# RL6955_IP_SVD register map
Vendor: Realtek
Registers are 32-bit, read-write, reset 0x0 unless marked. A register's access mark holds for its fields unless they carry their own. Offsets are from the block's base; [hi:lo] are bit positions; {n}, {i} and the like mark numbered series.

## MJPEG_REG
Base 0x418C0000
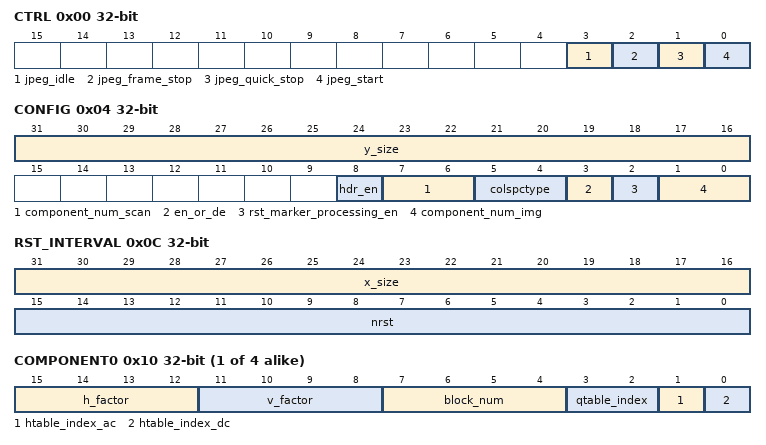
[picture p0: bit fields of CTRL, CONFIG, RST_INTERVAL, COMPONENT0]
0x00 CTRL access per field — MJPEG control register
  [3] jpeg_idle ro — jpeg idle status
  [2] jpeg_frame_stop wo — jpeg stop processing after current frame enc/dec done
  [1] jpeg_quick_stop wo — jpeg stop processing after current axi cmd complete.
  [0] jpeg_start wo — jpeg start processing
0x04 CONFIG — MJPEG config register
  [31:16] y_size — Number of lines in source image
  [8] hdr_en — Header Processing (generation/parsing) enabled when set
  [7:6] component_num_scan — Number of Components for Scan Header Marker Segment, minus one.
  [5:4] colspctype — colspctype defines the number of quantization tables to insert in the output stream minus one. 0 = Grayscale, 1 = YUV, 2 = RGB, 3 = CMYK
  [3] en_or_de — Selects encoding or decoding behavior. When this bit is set, the CODEC acts as a decoder; otherwise, it works as an encoder
  [2] rst_marker_processing_en — Enables restart marker processing when set. The ECS Encoder inserts restart markers every NRST +1 MCU
  [1:0] component_num_img — Number of color components in the source image minus 1. For example, in a grayscale image its value is 0; for a RGB or YUV image its value is = 2
0x08 MCUNUM — MJPEG MCU number register
  [25:0] mcu_num — Number of MCU units to encode minus 1
0x0C RST_INTERVAL — MJPEG reset interval control register
  [31:16] x_size — Number of pixels per line
  [15:0] nrst — NRST value is the number of MCUs between two restart markers minus 1. The content of this register is ignored if the rst_marker_processing_en bit is not set.
{0x10+4i} COMPONENT{i} (i=0..3) — MJPEG component register{i}
  [15:12] h_factor — Horizontal Sampling factor for component i.
  [11:8] v_factor — Vertical Sampling factor for component i.
  [7:4] block_num — The value is the number of data units (8 x 8 blocks of data) of the color component i contained in the MCU minus 1. The range is 0-15, because 4 bits are set aside for this field.
  [3:2] qtable_index — It indicates the quantization table to be used for the color component i. Since four quantization tables are possible, 2 bits are sufficient for this field (bits 3-2 in the register).
  [1] htable_index_ac — It selects the Huffman table for the encoding of the AC coefficients in the data units belonging to the color component i. Since only two AC tables are allowed in the baseline algorithm, one bit is sufficient (bit 1 in the register).
  [0] htable_index_dc — It bit selects the Huffman table for the encoding of the DC coefficient in the data units belonging to the color component i. Since only two DC tables are allowed in the baseline algorithm, one bit is sufficient (bit 0 in the register).
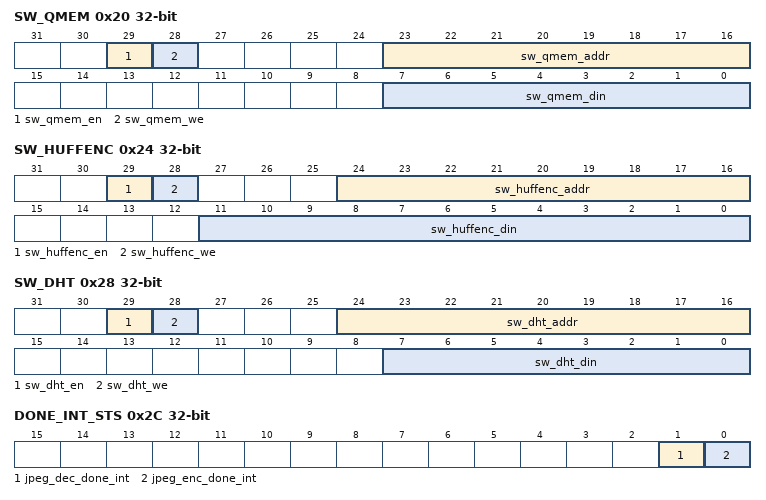
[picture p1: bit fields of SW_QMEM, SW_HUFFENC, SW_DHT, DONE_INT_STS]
0x20 SW_QMEM — MJPEG Qtable memory configuration
  [29] sw_qmem_en — Qtable configuration information, SRAM chip selection signal, write 1 when reading and writing
  [28] sw_qmem_we — Qtable configuration information, SRAM write enable
  [23:16] sw_qmem_addr — Qtable configuration information, selected address for SRAM
  [7:0] sw_qmem_din — Qtable configuration information, write SRAM value
0x24 SW_HUFFENC — MJPEG huffman memory configuration
  [29] sw_huffenc_en — huffman table configuration information, SRAM chip selection signal, write 1 when reading and writing
  [28] sw_huffenc_we — huffman table configuration information, SRAM write enable
  [24:16] sw_huffenc_addr — huffman table configuration information, selected address for SRAM
  [11:0] sw_huffenc_din — huffman table configuration information, write SRAM value
0x28 SW_DHT — MJPEG DQT memory configuration
  [29] sw_dht_en — DHT configuration information, SRAM chip selection signal, write 1 when reading and writing
  [28] sw_dht_we — DHT configuration information, SRAM write enable
  [24:16] sw_dht_addr — DHT configuration information, selected address for SRAM
  [7:0] sw_dht_din — DHT configuration information, write SRAM value
0x2C DONE_INT_STS ro — MJPEG encoder/decoder done interrupt status
  [1] jpeg_dec_done_int — JPEG decoding done interrupt (JPEG clock domain)
  [0] jpeg_enc_done_int — JPEG encoding done interrupt (JPEG clock domain)
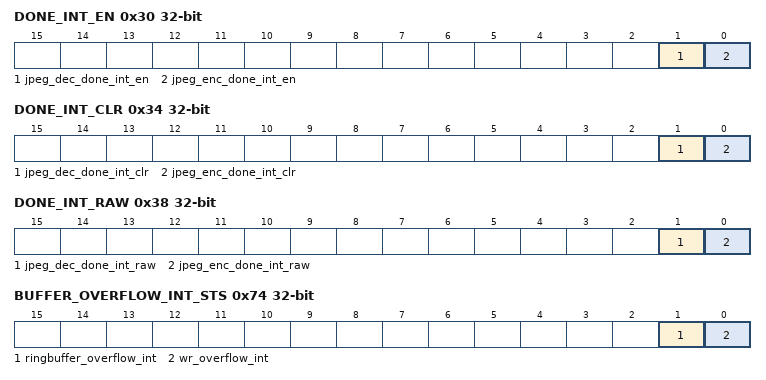
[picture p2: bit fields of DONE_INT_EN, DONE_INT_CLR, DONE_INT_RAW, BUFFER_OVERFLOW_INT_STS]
0x30 DONE_INT_EN — MJPEG encoder/decoder done interrupt enable signal
  [1] jpeg_dec_done_int_en — JPEG decoding interrupt enable signal
  [0] jpeg_enc_done_int_en — JPEG encoding interrupt enable signal
0x34 DONE_INT_CLR — MJPEG encoder/decoder done interrupt clear signal
  [1] jpeg_dec_done_int_clr — JPEG encoding interrupt clearing signal
  [0] jpeg_enc_done_int_clr — JPEG encoding interrupt clearing signal
0x38 DONE_INT_RAW ro — MJPEG encoder/decoder done interrupt raw status
  [1] jpeg_dec_done_int_raw — JPEG decoding done raw interrupt (JPEG clock domain)
  [0] jpeg_enc_done_int_raw — JPEG encoding done raw interrupt (JPEG clock domain)
0x3C RD_START_ADDR — MJPEG encoder/decoder reading buffer address
  [31:2] rd_start_addr — The starting address of the read during encoding or decoding, aligned with 4 bytes
0x40 RD_BUFFER_LEN — MJPEG encoder/decoder reading buffer length
  [23:0] rd_len — The length of the read during encoding or decoding
0x48 RING_BUFFER_MODE — MJPEG ringbuffer enable signal
  [0] ring_buffer_en — ring buffer enable signal
0x4C RING_BUFFER_SIZE — MJPEG ringbuffer size
  [5:0] ring_buffer_size — ring buffer size (unit: line). The ring buffer size must be a multiple of 8, while the DDR len of DVP is in byte units. When in ring buffer mode, it is necessary to satisfy the condition of ring_fuffer_stize * width * 2=DDR len
0x50 WR_START_ADDR — MJPEG encoder/decoder writeing buffer address
  [31:2] wr_start_addr — The starting address of the write during encoding or decoding, aligned with 4 bytes
{0x50+4i} ENC_WR_START_ADDR_{i} (i=1..3) — MJPEG ringbuffer address {i}
  [31:2] enc_wr_start_addr_{i} — the encoder stream write address for buffer{i} in the ring buffer mode, aligned with 4 bytes
0x60 WR_BUFFER_LEN — MJPEG writing buffer size
  [23:2] buffer_length — The size of the address space allocated to the encoder write stream, aligned with 4 bytes
0x64 ENC_BUFFER_RECEIVED_LENGTH ro — MJPEG received length of buffer0
  [22:0] buffer_received_length_0 — the received length of buffer0
{0x64+4i} ENC_BUFFER_RECEIVED_LENGTH_{i} ro (i=1..3) — MJPEG received length of buffer{i}
  [22:0] buffer_received_length_{i} — the received length of buffer{i}
0x74 BUFFER_OVERFLOW_INT_STS ro — MJPEG overflow interrupt status
  [1] ringbuffer_overflow_int — ring buffer overflow interrupt flag,indicate ringbuffer overflow during encoding
  [0] wr_overflow_int — write overflow interrupt flag,indicate write buffer is overflowed during encoding and decoding
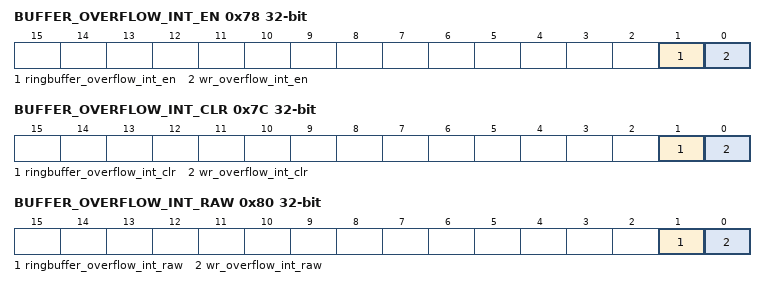
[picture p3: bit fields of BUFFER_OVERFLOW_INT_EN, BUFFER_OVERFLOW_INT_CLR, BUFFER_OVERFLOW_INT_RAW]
0x78 BUFFER_OVERFLOW_INT_EN — MJPEG overflow interrupt enable signal
  [1] ringbuffer_overflow_int_en — ring buffer overflow interrupt enable signal
  [0] wr_overflow_int_en — write overflow interrupt enable signal
0x7C BUFFER_OVERFLOW_INT_CLR — MJPEG overflow interrupt clear signal
  [1] ringbuffer_overflow_int_clr — ring buffer overflow interrupt clear signal
  [0] wr_overflow_int_clr — write overflow interrupt clear signal
0x80 BUFFER_OVERFLOW_INT_RAW ro — MJPEG overflow interrupt raw status
  [1] ringbuffer_overflow_int_raw — ring buffer overflow interrupt raw signal
  [0] wr_overflow_int_raw — write overflow interrupt raw signal
0x84 BUFFER_FRAME_NUM — MJPEG number of buffer in ringbufffer mode
  [2:0] buffer_frame_num — Indicates the number of buffers configured for encoding the output stream when encoding in ring buffer mode
0x88 BUFFER_FRAME_STATUS — MJPEG buffer status
  [3:0] buffer_frame_status — bits [0] [1] [2] [3] respectively represent the status of the buffer ([x] bit 1 indicates which buffer already contains a frame of encoded data)
0x8C BUFFER_FRAME_CNT ro — MJPEG using buffer index
  [1:0] buffer_frame_cnt — indicates which buffer is currently being written to
0x90 TIMEOUT_CFG — MJPEG timeout configuration
  [31:0] timeout_cfg — timeout value (unit: clock cycle)
0x94 TIMEOUT_CFG_EN — MJPEG timeout function enable
  [0] timeout_cfg_en — enable/disable timeout function
0x98 TIMEOUT_STS ro — MJPEG timeout interrupt status
  [0] timeout_int — timeout interrupt status
0x9C TIMEOUT_EN — MJPEG timeout interrupt enable signal
  [0] timeout_int_en — timeout interrupt enable
0xA0 TIMEOUT_CLR — MJPEG timeout interrupt clear signal
  [0] timeout_int_clr — timeout interrupt clear
0xA4 TIMEOUT_RAW ro — MJPEG timeout interrupt raw status
  [0] timeout_int_raw — timeout interrupt raw status
0xC0 BUFFER_CNT_OVERFLOW_INT_STS ro — MJPEG ringbuffer count overflow interrupt status
  [0] buffer_cnt_overflow_int — ringbuffer count overflow interrupt status
0xC4 BUFFER_CNT_OVERFLOW_INT_EN — MJPEG ringbuffer count overflow interrupt enable signal
  [0] buffer_cnt_overflow_int_en — ringbuffer count overflow interrupt enable signal
0xC8 BUFFER_CNT_OVERFLOW_INT_CLR — MJPEG ringbuffer count overflow interrupt clear signal
  [0] buffer_cnt_overflow_int_clr — ringbuffer count overflow interrupt clear signal
0xCC BUFFER_CNT_OVERFLOW_INT_RAW ro — MJPEG ringbuffer count overflow interrupt raw signal
  [0] buffer_cnt_overflow_int_raw — ringbuffer count overflow interrupt raw status
0xD0 MISS_FRAME_CNT ro — MJPEG ringbuffer miss frame count
  [0] miss_frame_cnt — ringbuffer miss frame count
